AUTOSAR XML (schema 4-0-3)
package /ComponentTypes
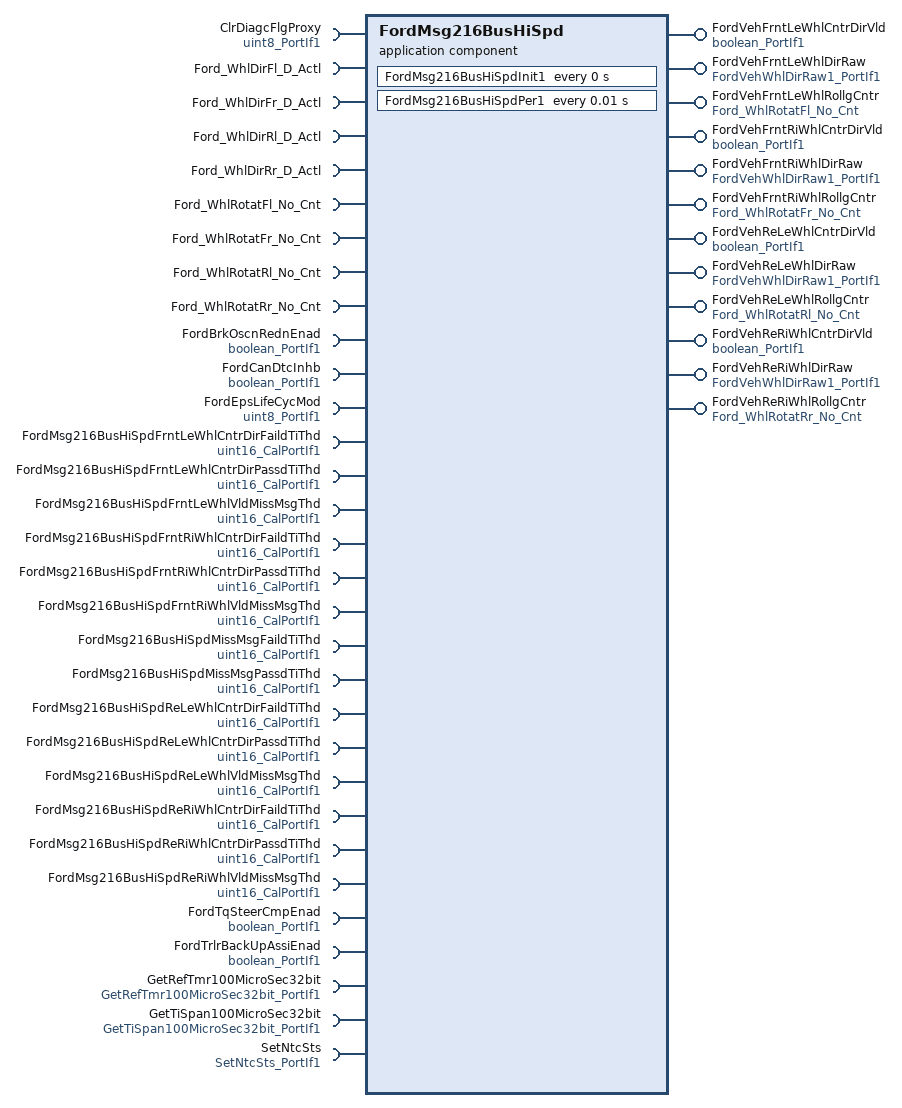
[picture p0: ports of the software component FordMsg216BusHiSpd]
  application sw component type FordMsg216BusHiSpd  # The purpose of the Ford Message 216 Bus High Speedfunction is to provide the Electric Power Steering system with signalvalues for the Trailer Back Up Assist, Torque Steer Compensation,and Brake Oscillation Reduction functions from CAN. The Ford Message216 function will perform the missing message diagnostic as wellas provide a validity signal for the received message.
    12 x provide port:
      FordVehFrntLeWhlCntrDirVld: nonqueued-sender-com-spec{data-element=Logl, init-value=0}, provided-interface=boolean_PortIf1  # This output tells if the value for Ford Vehicle Front Left WheelCounter Direction is valid or not
      FordVehFrntLeWhlDirRaw: nonqueued-sender-com-spec{data-element=Val, init-value=0}, provided-interface=FordVehWhlDirRaw1_PortIf1  # This signal provides the raw values of Ford Vehicle Front Left Wheel Direction
      FordVehFrntLeWhlRollgCntr: nonqueued-sender-com-spec{data-element=Ford_WhlRotatFl_No_Cnt, init-value=0}, provided-interface=Ford_WhlRotatFl_No_Cnt  # Processed value of Ford Vehicle Front Left Wheel Rolling Counter to be used by EPS
      FordVehFrntRiWhlCntrDirVld: nonqueued-sender-com-spec{data-element=Logl, init-value=0}, provided-interface=boolean_PortIf1  # 'This output tells if the value for Ford Vehicle Front Right WheelCounter Direction is valid or not
      FordVehFrntRiWhlDirRaw: nonqueued-sender-com-spec{data-element=Val, init-value=0}, provided-interface=FordVehWhlDirRaw1_PortIf1  # This signal provides the raw values of Ford Vehicle Front Right Wheel Direction
      FordVehFrntRiWhlRollgCntr: nonqueued-sender-com-spec{data-element=Ford_WhlRotatFr_No_Cnt, init-value=0}, provided-interface=Ford_WhlRotatFr_No_Cnt  # Processed value of Ford Vehicle Front Right Wheel Rolling Counter to be used by EPS
      FordVehReLeWhlCntrDirVld: nonqueued-sender-com-spec{data-element=Logl, init-value=0}, provided-interface=boolean_PortIf1  # This output tells if the value for Ford Vehicle Rear Left WheelCounter Direction is valid or not
      FordVehReLeWhlDirRaw: nonqueued-sender-com-spec{data-element=Val, init-value=0}, provided-interface=FordVehWhlDirRaw1_PortIf1  # This signal provides the raw values of Ford Vehicle Rear Left Wheel Direction
      FordVehReLeWhlRollgCntr: nonqueued-sender-com-spec{data-element=Ford_WhlRotatRl_No_Cnt, init-value=0}, provided-interface=Ford_WhlRotatRl_No_Cnt  # Processed value of Ford Vehicle Rear Left Wheel Rolling Counter to be used by EPS
      FordVehReRiWhlCntrDirVld: nonqueued-sender-com-spec{data-element=Logl, init-value=0}, provided-interface=boolean_PortIf1  # This output tells if the value for Ford Vehicle Rear Right WheelCounter Direction is valid or not
      FordVehReRiWhlDirRaw: nonqueued-sender-com-spec{data-element=Val, init-value=0}, provided-interface=FordVehWhlDirRaw1_PortIf1  # This signal provides the raw values of Ford Vehicle Rear Right Wheel Direction
      FordVehReRiWhlRollgCntr: nonqueued-sender-com-spec{data-element=Ford_WhlRotatRr_No_Cnt, init-value=0}, provided-interface=Ford_WhlRotatRr_No_Cnt  # Processed value of Ford Vehicle Rear Right Wheel Rolling Counter to be used by EPS
    31 x require port:
      ClrDiagcFlgProxy: nonqueued-receiver-com-spec{data-element=Val, filter=data-filter-type=ALWAYS, init-value=0}, required-interface=uint8_PortIf1  # When ClrDiagcFlgProxy is True, Diagnostic test is performed
      Ford_WhlDirFl_D_Actl: nonqueued-receiver-com-spec{data-element=Ford_WhlDirFl_D_Actl, filter=data-filter-type=ALWAYS, init-value=0}, required-interface=Ford_WhlDirFl_D_Actl  # It is a message signal which is received from CAN bus which will be processed and used in EPS. Datatype: Ford_WhlDirFl_D_Actl.Elements are: 0 - Cx0_Forward, 1 - Cx1_Backward, 2 - Cx2_Unknown, 3 - Cx3_Failed
      Ford_WhlDirFr_D_Actl: nonqueued-receiver-com-spec{data-element=Ford_WhlDirFr_D_Actl, filter=data-filter-type=ALWAYS, init-value=0}, required-interface=Ford_WhlDirFr_D_Actl  # It is a message signal which is received from CAN bus which will be processed and used in EPS.Datatype: Ford_WhlDirFr_D_Actl.Elements are: 0- Cx0_Forward, 1 - Cx1_Backward, 2 - Cx2_Unknown, 3 - Cx3_Failed
      Ford_WhlDirRl_D_Actl: nonqueued-receiver-com-spec{data-element=Ford_WhlDirRl_D_Actl, filter=data-filter-type=ALWAYS, init-value=0}, required-interface=Ford_WhlDirRl_D_Actl  # 'It is a message signal which is received from CAN bus which will be processed and used in EPS.Datatype: Ford_WhlDirRl_D_Actl.Elements are: 0- Cx0_Forward, 1 - Cx1_Backward, 2 - Cx2_Unknown, 3 - Cx3_Failed
      Ford_WhlDirRr_D_Actl: nonqueued-receiver-com-spec{data-element=Ford_WhlDirRr_D_Actl, filter=data-filter-type=ALWAYS, init-value=0}, required-interface=Ford_WhlDirRr_D_Actl  # It is a message signal which is received from CAN bus which will be processed and used in EPS.Datatype: Ford_WhlDirRr_D_Actl.Elements are: 0- Cx0_Forward, 1 - Cx1_Backward, 2 - Cx2_Unknown, 3 - Cx3_Failed
      Ford_WhlRotatFl_No_Cnt: nonqueued-receiver-com-spec{data-element=Ford_WhlRotatFl_No_Cnt, filter=data-filter-type=ALWAYS, init-value=0}, required-interface=Ford_WhlRotatFl_No_Cnt  # It is a message signal which is received from CAN bus which will be processed and used in EPS
      Ford_WhlRotatFr_No_Cnt: nonqueued-receiver-com-spec{data-element=Ford_WhlRotatFr_No_Cnt, filter=data-filter-type=ALWAYS, init-value=0}, required-interface=Ford_WhlRotatFr_No_Cnt  # It is a message signal which is received from CAN bus which will be processed and used in EPS
      Ford_WhlRotatRl_No_Cnt: nonqueued-receiver-com-spec{data-element=Ford_WhlRotatRl_No_Cnt, filter=data-filter-type=ALWAYS, init-value=0}, required-interface=Ford_WhlRotatRl_No_Cnt  # It is a message signal which is received from CAN bus which will be processed and used in EPS
      Ford_WhlRotatRr_No_Cnt: nonqueued-receiver-com-spec{data-element=Ford_WhlRotatRr_No_Cnt, filter=data-filter-type=ALWAYS, init-value=0}, required-interface=Ford_WhlRotatRr_No_Cnt  # It is a message signal which is received from CAN bus which will be processed and used in EPS
      FordBrkOscnRednEnad: nonqueued-receiver-com-spec{data-element=Logl, filter=data-filter-type=ALWAYS, init-value=0}, required-interface=boolean_PortIf1  # This signal checks wheather Diagnostics needs to be performed or reset of timer and NTC is required. Customer Datatype should be used.Data Type: Boolean with Min value False(0), Init value False(0) and Max value True(1)
      FordCanDtcInhb: nonqueued-receiver-com-spec{data-element=Logl, filter=data-filter-type=ALWAYS, init-value=1}, required-interface=boolean_PortIf1  # When CAN DTC Inhibit is FALSE, Diagnostic test is performedCustomer Datatype should be used.Data Type: Boolean with Minvalue False(0), Init value True(1) and Max value True(1)
      FordEpsLifeCycMod: nonqueued-receiver-com-spec{data-element=Val, filter=data-filter-type=ALWAYS, init-value=0}, required-interface=uint8_PortIf1  # This signal is used to decide calibration value to FAIL the NTC
      FordMsg216BusHiSpdFrntLeWhlCntrDirFaildTiThd: parameter-require-com-spec{init-value=0, parameter=Val}, required-interface=uint16_CalPortIf1  # Threshold to set the output Front Left Wheel Counter Direction Valid to False
      FordMsg216BusHiSpdFrntLeWhlCntrDirPassdTiThd: parameter-require-com-spec{init-value=0, parameter=Val}, required-interface=uint16_CalPortIf1  # Threshold to set the output Front Left Wheel Counter Direction Valid to True
      FordMsg216BusHiSpdFrntLeWhlVldMissMsgThd: parameter-require-com-spec{init-value=5000, parameter=Val}, required-interface=uint16_CalPortIf1  # Threshold to set the output Ford Vehicle Front Left Wheel Counter Direction Valid to False
      FordMsg216BusHiSpdFrntRiWhlCntrDirFaildTiThd: parameter-require-com-spec{init-value=0, parameter=Val}, required-interface=uint16_CalPortIf1  # Threshold to set the output Front Right Wheel Counter Direction Valid to False
      FordMsg216BusHiSpdFrntRiWhlCntrDirPassdTiThd: parameter-require-com-spec{init-value=0, parameter=Val}, required-interface=uint16_CalPortIf1  # Threshold to set the output Front Right Wheel Counter Direction Valid to True
      FordMsg216BusHiSpdFrntRiWhlVldMissMsgThd: parameter-require-com-spec{init-value=5000, parameter=Val}, required-interface=uint16_CalPortIf1  # Threshold to set the output Ford Vehicle Front Right Wheel Counter Direction Valid to False
      FordMsg216BusHiSpdMissMsgFaildTiThd: parameter-require-com-spec{init-value=5000, parameter=Val}, required-interface=uint16_CalPortIf1  # Threshold to Set the Missing message NTC
      FordMsg216BusHiSpdMissMsgPassdTiThd: parameter-require-com-spec{init-value=0, parameter=Val}, required-interface=uint16_CalPortIf1  # Threshold to Reset the Missing message NTC
      FordMsg216BusHiSpdReLeWhlCntrDirFaildTiThd: parameter-require-com-spec{init-value=0, parameter=Val}, required-interface=uint16_CalPortIf1  # Threshold to set the output Rear Left Wheel Counter Direction Valid to False
      FordMsg216BusHiSpdReLeWhlCntrDirPassdTiThd: parameter-require-com-spec{init-value=0, parameter=Val}, required-interface=uint16_CalPortIf1  # Threshold to set the output Rear Left Wheel Counter Direction Valid to True
      FordMsg216BusHiSpdReLeWhlVldMissMsgThd: parameter-require-com-spec{init-value=5000, parameter=Val}, required-interface=uint16_CalPortIf1  # Threshold to set the output Ford Vehicle Rear Left Wheel Counter Direction Valid to False
      FordMsg216BusHiSpdReRiWhlCntrDirFaildTiThd: parameter-require-com-spec{init-value=0, parameter=Val}, required-interface=uint16_CalPortIf1  # Threshold to set the output Rear Right Wheel Counter Direction Valid to False
      FordMsg216BusHiSpdReRiWhlCntrDirPassdTiThd: parameter-require-com-spec{init-value=0, parameter=Val}, required-interface=uint16_CalPortIf1  # Threshold to set the output Rear Right Wheel Counter Direction Valid to True
      FordMsg216BusHiSpdReRiWhlVldMissMsgThd: parameter-require-com-spec{init-value=5000, parameter=Val}, required-interface=uint16_CalPortIf1  # Threshold to set the output Ford Vehicle Rear Right Wheel Counter Direction Valid to False
      FordTqSteerCmpEnad: nonqueued-receiver-com-spec{data-element=Logl, filter=data-filter-type=ALWAYS, init-value=0}, required-interface=boolean_PortIf1  # This signal checks wheather Diagnostics needs to be performed or reset of timer and NTC is required.Customer Datatype should be used.Data Type: Boolean with Min value False(0), Init value False(0) and Max value True(1)
      FordTrlrBackUpAssiEnad: nonqueued-receiver-com-spec{data-element=Logl, filter=data-filter-type=ALWAYS, init-value=0}, required-interface=boolean_PortIf1  # This signal checks wheather Diagnostics needs to be performed or reset of timer and NTC is required Customer Datatype should be used.Data Type: Boolean with Min value False(0), Init value False(0) and Max value True(1)
      GetRefTmr100MicroSec32bit: client-com-spec=Oper, required-interface=GetRefTmr100MicroSec32bit_PortIf1  # It captures simulation time fromthe SimnTi value obtained at root layer of model and gives the RefTmr.
      GetTiSpan100MicroSec32bit: client-com-spec=Oper, required-interface=GetTiSpan100MicroSec32bit_PortIf1  # It Captures simulation time fromSimnTi value, handles counter wrapping, and subtracts RefTmr,provides the TiSpan
      SetNtcSts: client-com-spec=Oper, required-interface=SetNtcSts_PortIf1  # Returns the NTC Qualifier status
    behavior FordMsg216BusHiSpd_InternalBehavior
      ar-typed-per-instance-memorys:
        29 x data, all with sw-calibration-access=READ-ONLY:
          ClrDiagcFlgProxyPrev: type=uint8  # Clear Diagc Flag Proxy
          FirstTranVldFlg: type=boolean  # This flag is used to indicate the reception of first message
          FordVehFrntLeWhlCntrDirVldPrev: type=boolean  # Previous value of Ford Vehicle Front Left Wheel Counter Direction Valid
          FordVehFrntLeWhlDirRawPrev: type=FordVehWhlDirRaw1  # Previous value of Ford Vehicle Front Left Wheel Direction Raw
          FordVehFrntLeWhlRollgCntrPrev: type=uint8  # Previous value of Ford Vehicle Front Left Wheel Rolling Counter
          FordVehFrntRiWhlCntrDirVldPrev: type=boolean  # Previous value of Ford Vehicle Front Right Wheel Counter Direction Valid
          FordVehFrntRiWhlDirRawPrev: type=FordVehWhlDirRaw1  # Previous value of Ford Vehicle Front Right Wheel Direction Raw
          FordVehFrntRiWhlRollgCntrPrev: type=uint8  # Previous value of Ford Vehicle Front Right Wheel Rolling Counter
          FordVehMsg064Miss: type=boolean  # Flag for missing message diagnostics, it is true when message is missing
          FordVehReLeWhlCntrDirVldPrev: type=boolean  # Previous value of Ford Vehicle Rear Left Wheel Counter Direction Valid
          FordVehReLeWhlDirRawPrev: type=FordVehWhlDirRaw1  # Previous value of Ford Vehicle Rear Left Wheel Direction Raw
          FordVehReLeWhlRollgCntrPrev: type=uint8  # Previous value of Ford Vehicle Rear Left Wheel Rolling Counter
          FordVehReRiWhlCntrDirVldPrev: type=boolean  # Previous value of Ford Vehicle Rear Right Wheel Counter Direction Valid
          FordVehReRiWhlDirRawPrev: type=FordVehWhlDirRaw1  # Previous value of Ford Vehicle Rear Right Wheel Direction Raw
          FordVehReRiWhlRollgCntrPrev: type=uint8  # Previous value of Ford Vehicle Rear Right Wheel Rolling Counter
          FrntLeWhlCntrDirVldFaildRefTi: type=uint32  # tLeWhlCntrDirVldFaildRefTi.Description = [Timer for Front Left Wheel Counter Direction Valid Failed Reference Time will increment or reset based on the conditions
          FrntLeWhlCntrDirVldPassdRefTi: type=uint32  # Timer for Front Left Wheel Counter Direction Valid Passed Reference Ti'me will increment or reset based on the conditions
          FrntLeWhlVldMissMsgRefTi: type=uint32  # Timer for Front Left Wheel Counter Direction Valid Missing Message Reference Time will increment or reset based on the conditions
          FrntRiWhlCntrDirVldFaildRefTi: type=uint32  # 'Timer for Front Right Wheel Counter Direction Valid Failed Reference Time will increment or reset based on the conditions
          FrntRiWhlCntrDirVldPassdRefTi: type=uint32  # Timer for Front Right Wheel Counter Direction Valid Passed Reference Time will increment or reset based on the conditions
          FrntRiWhlVldMissMsgRefTi: type=uint32  # Timer for Front Right Wheel Counter Direction Valid Missing Message Reference Time will increment or reset based on the conditions
          MissMsgFaildRefTi: type=uint32  # Timer for misisng message will increment or reset based on the conditions
          MissMsgPassdRefTi: type=uint32  # Timer for misisng message will increment or reset based on the conditions
          ReLeWhlCntrDirVldFaildRefTi: type=uint32  # Timer for Rear Left Wheel Counter Direction Valid Failed Reference Time will increment or reset based on the conditions
          ReLeWhlCntrDirVldPassdRefTi: type=uint32  # Timer for Rear Left Wheel Counter Direction Valid Passed Reference Time will increment or reset based on the conditions
          ReLeWhlVldMissMsgRefTi: type=uint32  # Timer for Rear Left Wheel Counter Direction Valid Missing Message Reference Time will increment or reset based on the conditions
          ReRiWhlCntrDirVldFaildRefTi: type=uint32  # Timer for Rear Right Wheel Counter Direction Valid Failed Reference Time will increment or reset based on the conditions
          ReRiWhlCntrDirVldPassdRefTi: type=uint32  # Timer for Rear Right Wheel Counter Direction Valid Passed Reference Time will increment or reset based on the conditions
          ReRiWhlVldMissMsgRefTi: type=uint32
      timing event FordMsg216BusHiSpd_InitEvent: start-on-event=FordMsg216BusHiSpdInit1, period=0
      timing event TMT_FordMsg216BusHiSpdPer1: start-on-event=FordMsg216BusHiSpdPer1, period=0.01
      port-api-options:
        enable-take-address=false, indirect-api=false, port=ClrDiagcFlgProxy
        enable-take-address=false, indirect-api=false, port=Ford_WhlDirFl_D_Actl
        enable-take-address=false, indirect-api=false, port=Ford_WhlDirFr_D_Actl
        enable-take-address=false, indirect-api=false, port=Ford_WhlDirRl_D_Actl
        enable-take-address=false, indirect-api=false, port=Ford_WhlDirRr_D_Actl
        enable-take-address=false, indirect-api=false, port=Ford_WhlRotatFl_No_Cnt
        enable-take-address=false, indirect-api=false, port=Ford_WhlRotatFr_No_Cnt
        enable-take-address=false, indirect-api=false, port=Ford_WhlRotatRl_No_Cnt
        enable-take-address=false, indirect-api=false, port=Ford_WhlRotatRr_No_Cnt
        enable-take-address=false, indirect-api=false, port=FordBrkOscnRednEnad
        enable-take-address=false, indirect-api=false, port=FordCanDtcInhb
        enable-take-address=false, indirect-api=false, port=FordEpsLifeCycMod
        enable-take-address=false, indirect-api=false, port=FordMsg216BusHiSpdFrntLeWhlCntrDirFaildTiThd
        enable-take-address=false, indirect-api=false, port=FordMsg216BusHiSpdFrntLeWhlCntrDirPassdTiThd
        enable-take-address=false, indirect-api=false, port=FordMsg216BusHiSpdFrntLeWhlVldMissMsgThd
        enable-take-address=false, indirect-api=false, port=FordMsg216BusHiSpdFrntRiWhlCntrDirFaildTiThd
        enable-take-address=false, indirect-api=false, port=FordMsg216BusHiSpdFrntRiWhlCntrDirPassdTiThd
        enable-take-address=false, indirect-api=false, port=FordMsg216BusHiSpdFrntRiWhlVldMissMsgThd
        enable-take-address=false, indirect-api=false, port=FordMsg216BusHiSpdMissMsgFaildTiThd
        enable-take-address=false, indirect-api=false, port=FordMsg216BusHiSpdMissMsgPassdTiThd
        enable-take-address=false, indirect-api=false, port=FordMsg216BusHiSpdReLeWhlCntrDirFaildTiThd
        enable-take-address=false, indirect-api=false, port=FordMsg216BusHiSpdReLeWhlCntrDirPassdTiThd
        enable-take-address=false, indirect-api=false, port=FordMsg216BusHiSpdReLeWhlVldMissMsgThd
        enable-take-address=false, indirect-api=false, port=FordMsg216BusHiSpdReRiWhlCntrDirFaildTiThd
        enable-take-address=false, indirect-api=false, port=FordMsg216BusHiSpdReRiWhlCntrDirPassdTiThd
        enable-take-address=false, indirect-api=false, port=FordMsg216BusHiSpdReRiWhlVldMissMsgThd
        enable-take-address=false, indirect-api=false, port=FordTqSteerCmpEnad
        enable-take-address=false, indirect-api=false, port=FordTrlrBackUpAssiEnad
        enable-take-address=false, indirect-api=false, port=FordVehFrntLeWhlCntrDirVld
        enable-take-address=false, indirect-api=false, port=FordVehFrntLeWhlDirRaw
        enable-take-address=false, indirect-api=false, port=FordVehFrntLeWhlRollgCntr
        enable-take-address=false, indirect-api=false, port=FordVehFrntRiWhlCntrDirVld
        enable-take-address=false, indirect-api=false, port=FordVehFrntRiWhlDirRaw
        enable-take-address=false, indirect-api=false, port=FordVehFrntRiWhlRollgCntr
        enable-take-address=false, indirect-api=false, port=FordVehReLeWhlCntrDirVld
        enable-take-address=false, indirect-api=false, port=FordVehReLeWhlDirRaw
        enable-take-address=false, indirect-api=false, port=FordVehReLeWhlRollgCntr
        enable-take-address=false, indirect-api=false, port=FordVehReRiWhlCntrDirVld
        enable-take-address=false, indirect-api=false, port=FordVehReRiWhlDirRaw
        enable-take-address=false, indirect-api=false, port=FordVehReRiWhlRollgCntr
        enable-take-address=false, indirect-api=false, port=GetRefTmr100MicroSec32bit
        enable-take-address=false, indirect-api=false, port=GetTiSpan100MicroSec32bit
        enable-take-address=false, indirect-api=false, port=SetNtcSts
      runnable FordMsg216BusHiSpdInit1  # Initialization Runnable
        sync call SC_GetRefTmr100MicroSec32bit_Oper: operation=GetRefTmr100MicroSec32bit.Oper, timeout=0
      runnable FordMsg216BusHiSpdPer1  # Periodic Runnable at 0.002 sec
        data-receive-point-by-arguments:
          14 x access:
            REC_ClrDiagcFlgProxy_Val: accessed-variable=ClrDiagcFlgProxy.Val
            REC_Ford_WhlDirFl_D_Actl_Ford_WhlDirFl_D_Actl: accessed-variable=Ford_WhlDirFl_D_Actl.Ford_WhlDirFl_D_Actl
            REC_Ford_WhlDirFr_D_Actl_Ford_WhlDirFr_D_Actl: accessed-variable=Ford_WhlDirFr_D_Actl.Ford_WhlDirFr_D_Actl
            REC_Ford_WhlDirRl_D_Actl_Ford_WhlDirRl_D_Actl: accessed-variable=Ford_WhlDirRl_D_Actl.Ford_WhlDirRl_D_Actl
            REC_Ford_WhlDirRr_D_Actl_Ford_WhlDirRr_D_Actl: accessed-variable=Ford_WhlDirRr_D_Actl.Ford_WhlDirRr_D_Actl
            REC_Ford_WhlRotatFl_No_Cnt_Ford_WhlRotatFl_No_Cnt: accessed-variable=Ford_WhlRotatFl_No_Cnt.Ford_WhlRotatFl_No_Cnt
            REC_Ford_WhlRotatFr_No_Cnt_Ford_WhlRotatFr_No_Cnt: accessed-variable=Ford_WhlRotatFr_No_Cnt.Ford_WhlRotatFr_No_Cnt
            REC_Ford_WhlRotatRl_No_Cnt_Ford_WhlRotatRl_No_Cnt: accessed-variable=Ford_WhlRotatRl_No_Cnt.Ford_WhlRotatRl_No_Cnt
            REC_Ford_WhlRotatRr_No_Cnt_Ford_WhlRotatRr_No_Cnt: accessed-variable=Ford_WhlRotatRr_No_Cnt.Ford_WhlRotatRr_No_Cnt
            REC_FordBrkOscnRednEnad_Logl: accessed-variable=FordBrkOscnRednEnad.Logl
            REC_FordCanDtcInhb_Logl: accessed-variable=FordCanDtcInhb.Logl
            REC_FordEpsLifeCycMod_Val: accessed-variable=FordEpsLifeCycMod.Val
            REC_FordTqSteerCmpEnad_Logl: accessed-variable=FordTqSteerCmpEnad.Logl
            REC_FordTrlrBackUpAssiEnad_Logl: accessed-variable=FordTrlrBackUpAssiEnad.Logl
        data-send-points:
          12 x access:
            SEND_FordVehFrntLeWhlCntrDirVld_Logl: accessed-variable=FordVehFrntLeWhlCntrDirVld.Logl
            SEND_FordVehFrntLeWhlDirRaw_Val: accessed-variable=FordVehFrntLeWhlDirRaw.Val
            SEND_FordVehFrntLeWhlRollgCntr_Ford_WhlRotatFl_No_Cnt: accessed-variable=FordVehFrntLeWhlRollgCntr.Ford_WhlRotatFl_No_Cnt
            SEND_FordVehFrntRiWhlCntrDirVld_Logl: accessed-variable=FordVehFrntRiWhlCntrDirVld.Logl
            SEND_FordVehFrntRiWhlDirRaw_Val: accessed-variable=FordVehFrntRiWhlDirRaw.Val
            SEND_FordVehFrntRiWhlRollgCntr_Ford_WhlRotatFr_No_Cnt: accessed-variable=FordVehFrntRiWhlRollgCntr.Ford_WhlRotatFr_No_Cnt
            SEND_FordVehReLeWhlCntrDirVld_Logl: accessed-variable=FordVehReLeWhlCntrDirVld.Logl
            SEND_FordVehReLeWhlDirRaw_Val: accessed-variable=FordVehReLeWhlDirRaw.Val
            SEND_FordVehReLeWhlRollgCntr_Ford_WhlRotatRl_No_Cnt: accessed-variable=FordVehReLeWhlRollgCntr.Ford_WhlRotatRl_No_Cnt
            SEND_FordVehReRiWhlCntrDirVld_Logl: accessed-variable=FordVehReRiWhlCntrDirVld.Logl
            SEND_FordVehReRiWhlDirRaw_Val: accessed-variable=FordVehReRiWhlDirRaw.Val
            SEND_FordVehReRiWhlRollgCntr_Ford_WhlRotatRr_No_Cnt: accessed-variable=FordVehReRiWhlRollgCntr.Ford_WhlRotatRr_No_Cnt
        sync call SC_GetRefTmr100MicroSec32bit_Oper: operation=GetRefTmr100MicroSec32bit.Oper, timeout=0
        sync call SC_GetTiSpan100MicroSec32bit_Oper: operation=GetTiSpan100MicroSec32bit.Oper, timeout=0
        sync call SC_SetNtcSts_Oper: operation=SetNtcSts.Oper, timeout=0
  swc implementation FordMsg216BusHiSpd_Implementation: behavior=FordMsg216BusHiSpd_InternalBehavior
    code-descriptors:
      code Default: artifact-descriptors=autosar-engineering-object={short-label=Default, category=SWSRC}
